# STM32H7P4xx register map
File version: 1.0
Registers are 32-bit, read-write, reset 0x0 unless marked. A register's access mark holds for its fields unless they carry their own. Offsets are from the block's base; [hi:lo] are bit positions; {n}, {i} and the like mark numbered series.

## TAMP — Tamper and backup registers (TAMP)
Base 0x58004400
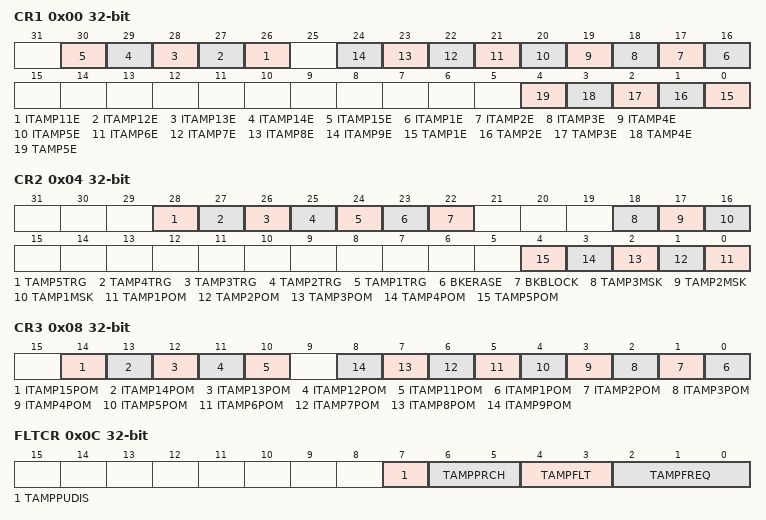
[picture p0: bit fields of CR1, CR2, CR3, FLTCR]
0x00 CR1 — TAMP control register 1
  [n+15] ITAMP{n}E (n=11..15) — Internal tamper {n} enable
  [n+15] ITAMP{n}E (n=1..9) — Internal tamper {n} enable
  [n-1] TAMP{n}E (n=1..5) — Tamper detection on TAMP_IN{n} enable
0x04 CR2 — TAMP control register 2
  [28] TAMP5TRG — Active level for tamper 5 input (active mode disabled)
  [27] TAMP4TRG — Active level for tamper 4 input (active mode disabled)
  [26] TAMP3TRG — Active level for tamper 3 input
  [25] TAMP2TRG — Active level for tamper 2 input
  [24] TAMP1TRG — Active level for tamper 1 input
  [23] BKERASE — Backup registers and device secrets erase
  [22] BKBLOCK — Backup registers and device secrets access blocked
  [18] TAMP3MSK — Tamper 3 mask
  [17] TAMP2MSK — Tamper 2 mask
  [16] TAMP1MSK — Tamper 1 mask
  [n-1] TAMP{n}POM (n=1..5) — Tamper {n} potential mode
0x08 CR3 — TAMP control register 3
  [14] ITAMP15POM — Internal tamper 15 potential mode
  [13] ITAMP14POM — Internal Tamper 14 potential mode
  [12] ITAMP13POM — Internal tamper 13 potential mode
  [11] ITAMP12POM — Internal tamper 12 potential mode
  [10] ITAMP11POM — Internal tamper 11 potential mode
  [n-1] ITAMP{n}POM (n=1..9) — Internal tamper {n} potential mode
0x0C FLTCR — TAMP filter control register
  [7] TAMPPUDIS — TAMP_INx pull-up disable
  [6:5] TAMPPRCH — TAMP_INx precharge duration
  [4:3] TAMPFLT — TAMP_INx filter count
  [2:0] TAMPFREQ — Tamper sampling frequency
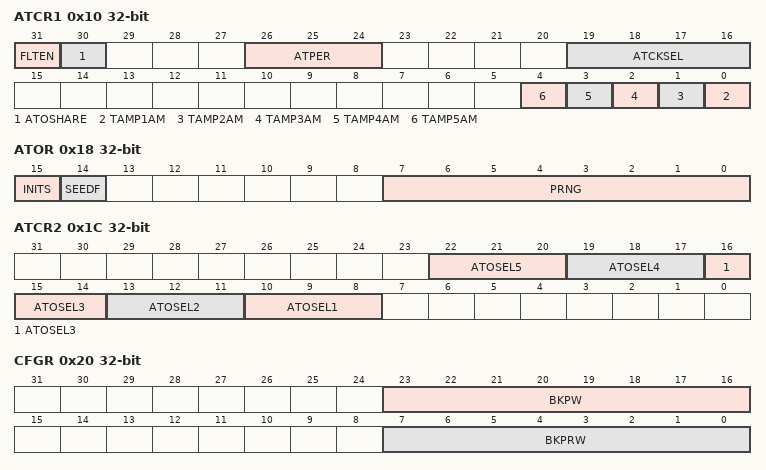
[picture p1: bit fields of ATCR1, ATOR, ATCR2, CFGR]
0x10 ATCR1 — TAMP active tamper control register 1
  [31] FLTEN — Active tamper filter enable
  [30] ATOSHARE — Active tamper output sharing
  [26:24] ATPER — Active tamper output change period
  [19:16] ATCKSEL — Active tamper RTC asynchronous prescaler clock selection
  [n-1] TAMP{n}AM (n=1..5) — Tamper {n} active mode
0x14 ATSEEDR — TAMP active tamper seed register
  [31:0] SEED — Pseudo-random generator seed value
0x18 ATOR ro — TAMP active tamper output register
  [15] INITS — Active tamper initialization status
  [14] SEEDF — Seed running flag
  [7:0] PRNG — Pseudo-random generator value
0x1C ATCR2 — TAMP active tamper control register 2
  [3n+7:3n+5] ATOSEL{n} (n=1..5) — Active tamper shared output {n} selection
0x20 CFGR — TAMP configuration register
  [23:16] BKPW — Backup registers write protection offset
  [7:0] BKPRW — Backup registers read/write protection offset
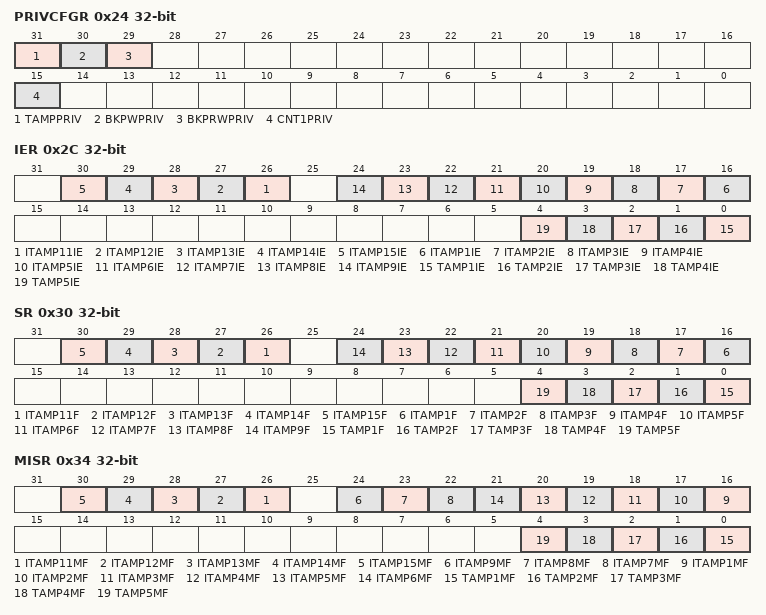
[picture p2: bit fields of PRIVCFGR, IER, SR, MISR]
0x24 PRIVCFGR — TAMP privilege configuration register
  [31] TAMPPRIV — Tamper privilege protection (excluding backup registers)
  [30] BKPWPRIV — Backup registers zone 2 privilege protection
  [29] BKPRWPRIV — Backup registers zone 1 privilege protection
  [15] CNT1PRIV — Monotonic counter 1 privilege protection
0x2C IER — TAMP interrupt enable register
  [n+15] ITAMP{n}IE (n=11..15) — Internal tamper {n} interrupt enable
  [n+15] ITAMP{n}IE (n=1..9) — Internal tamper {n} interrupt enable
  [n-1] TAMP{n}IE (n=1..5) — Tamper {n} interrupt enable
0x30 SR ro — TAMP status register
  [n+15] ITAMP{n}F (n=11..15) — Internal tamper {n} flag
  [n+15] ITAMP{n}F (n=1..9) — Internal tamper {n} flag
  [n-1] TAMP{n}F (n=1..5) — TAMP{n} detection flag
0x34 MISR ro — TAMP masked interrupt status register
  [n+15] ITAMP{n}MF (n=11..15) — internal tamper {n} interrupt masked flag
  [24] ITAMP9MF — internal tamper 9 interrupt masked flag
  [23] ITAMP8MF — Internal tamper 8 interrupt masked flag
  [22] ITAMP7MF — Internal tamper 7 tamper interrupt masked flag
  [n+15] ITAMP{n}MF (n=1..6) — Internal tamper {n} interrupt masked flag
  [n-1] TAMP{n}MF (n=1..5) — TAMP{n} interrupt masked flag
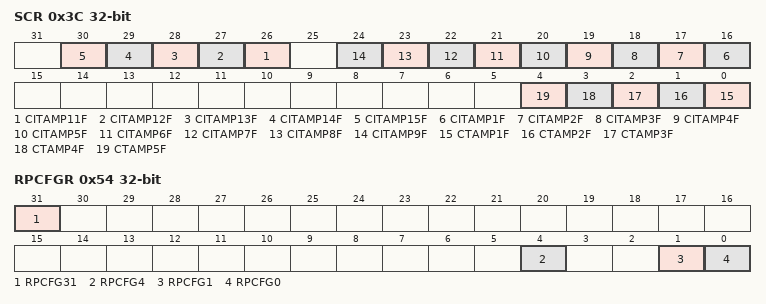
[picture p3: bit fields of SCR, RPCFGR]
0x3C SCR — TAMP status clear register
  [n+15] CITAMP{n}F (n=11..15) — Clear ITAMP{n} detection flag
  [n+15] CITAMP{n}F (n=1..9) — Clear ITAMP{n} detection flag
  [n-1] CTAMP{n}F (n=1..5) — Clear TAMP{n} detection flag
0x40 COUNT1R — TAMP monotonic counter 1 register
  [31:0] COUNT — This register is read-only only and is incremented by one when a write access is done to this regis
0x54 RPCFGR — TAMP resources protection configuration register
  [31] RPCFG31 — Backup registers protection
  [4] RPCFG4 — Configurable resource 4 protection
  [1] RPCFG1 — Configurable resource 1 protection
  [0] RPCFG0 — Configurable resource 0 protection
{0x100+4i} BKP{i}R (i=0..31) — TAMP backup {i} register
  [31:0] BKP — The application can write or read data to and from these registers
